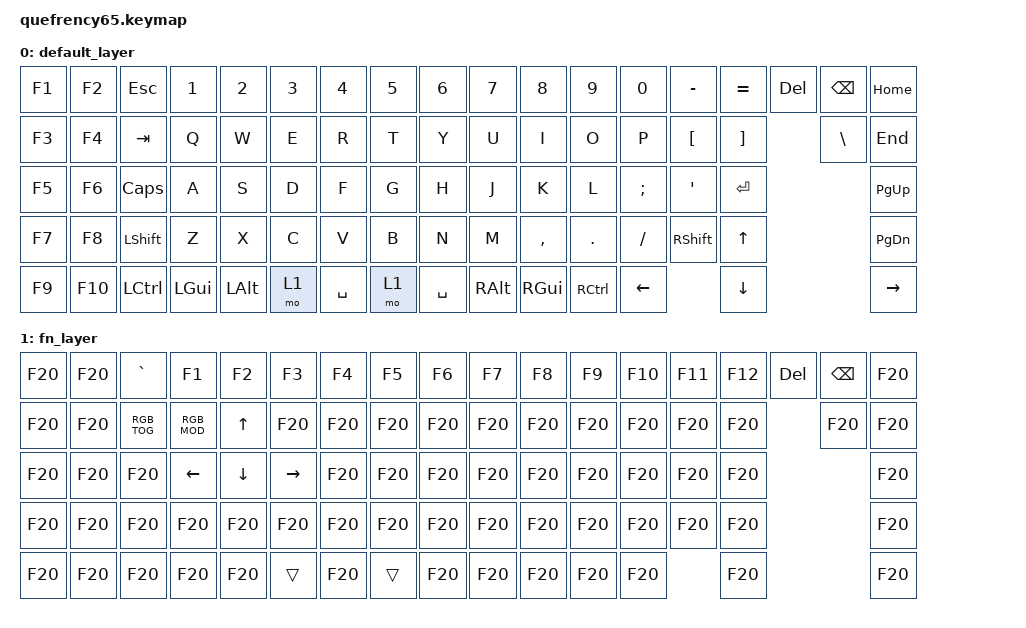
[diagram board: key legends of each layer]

  /*
  * Copyright (c) 2020 The ZMK Contributors
  *
  * SPDX-License-Identifier: MIT
  */

  #include <behaviors.dtsi>
  #include <dt-bindings/zmk/keys.h>
  #include <dt-bindings/zmk/bt.h>
  #include <dt-bindings/zmk/ext_power.h>

  / {
    keymap {
      compatible = "zmk,keymap";
  default_layer {
          bindings = <
          &kp F1 &kp F2   &kp ESCAPE       &kp N1       &kp N2       &kp N3     &kp N4      &kp N5  &kp N6      &kp N7          &kp N8          &kp N9              &kp N0          &kp MINUS           &kp EQUAL           &kp DELETE &kp BACKSPACE &kp HOME 
          &kp F3 &kp F4   &kp TAB          &kp Q        &kp W        &kp E      &kp R       &kp T   &kp Y       &kp U           &kp I           &kp O               &kp P           &kp LEFT_BRACKET    &kp RIGHT_BRACKET              &kp BACKSLASH &kp END 
          &kp F5 &kp F6   &kp CAPSLOCK     &kp A        &kp S        &kp D      &kp F       &kp G   &kp H       &kp J           &kp K           &kp L               &kp SEMICOLON   &kp SINGLE_QUOTE    &kp ENTER                                    &kp PAGE_UP 
          &kp F7 &kp F8   &kp LEFT_SHIFT   &kp Z        &kp X        &kp C      &kp V       &kp B   &kp N       &kp M           &kp COMMA       &kp DOT             &kp SLASH       &kp RIGHT_SHIFT     &kp UP                                       &kp PAGE_DOWN 
          &kp F9 &kp F10  &kp LEFT_CONTROL &kp LEFT_GUI &kp LEFT_ALT &mo 1      &kp SPACE   &mo 1   &kp SPACE   &kp RIGHT_ALT   &kp RIGHT_GUI   &kp RIGHT_CONTROL   &kp LEFT                            &kp DOWN                                     &kp RIGHT
          >;
        };
        
  fn_layer {
          bindings = <
          &kp F20 &kp F20 &kp GRAVE &kp F1  &kp F2 &kp F3   &kp F4  &kp F5  &kp F6  &kp F7  &kp F8  &kp F9  &kp F10 &kp F11 &kp F12 &kp DELETE  &kp BACKSPACE &kp F20 
          &kp F20 &kp F20 RGB_TOG   RGB_MOD &kp UP &kp F20  &kp F20 &kp F20 &kp F20 &kp F20 &kp F20 &kp F20 &kp F20 &kp F20 &kp F20 &kp F20     &kp F20       
          &kp F20 &kp F20 &kp F20 &kp LEFT &kp DOWN &kp RIGHT &kp F20 &kp F20 &kp F20 &kp F20 &kp F20 &kp F20 &kp F20 &kp F20 &kp F20 &kp F20 &kp F20 &kp F20 &kp F20 &kp F20 &kp F20 &kp F20 &kp F20 &kp F20 &kp F20 &kp F20 &kp F20 &kp F20 &kp F20 &kp F20 &kp F20 &kp F20 
          &kp F20 &kp F20 &kp F20 &kp F20 &kp F20 &trans &kp F20 &trans &kp F20 &kp F20 &kp F20 &kp F20 &kp F20 &kp F20 &kp F20
          >;
        };
    };
  };
  
